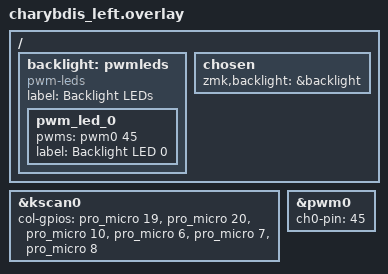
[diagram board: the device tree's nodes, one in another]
/*
 * Copyright (c) 2020 ZMK Contributors
 *
 * SPDX-License-Identifier: MIT
 */

#include "charybdis.dtsi"

&kscan0 {
	col-gpios
		= <&pro_micro 19 (GPIO_ACTIVE_HIGH | GPIO_PULL_DOWN)>
		, <&pro_micro 20 (GPIO_ACTIVE_HIGH | GPIO_PULL_DOWN)>
		, <&pro_micro 10 (GPIO_ACTIVE_HIGH | GPIO_PULL_DOWN)>
		, <&pro_micro 6 (GPIO_ACTIVE_HIGH | GPIO_PULL_DOWN)>
		, <&pro_micro 7 (GPIO_ACTIVE_HIGH | GPIO_PULL_DOWN)>
		, <&pro_micro 8 (GPIO_ACTIVE_HIGH | GPIO_PULL_DOWN)>
		;
};

&pwm0 {
    status = "okay";
    ch0-pin = <45>;
};

/ {
    backlight: pwmleds {
        compatible = "pwm-leds";
        label = "Backlight LEDs";
        pwm_led_0 {
            pwms = <&pwm0 45>;
            label = "Backlight LED 0";
        };
    };
};

/ {
    chosen {
        zmk,backlight = &backlight;
    };
}:
